# MB9BF52xT register map
File version: 1.2
CPU: 
Registers are 8-bit, read-write, reset 0x0 unless marked. A register's access mark holds for its fields unless they carry their own. Offsets are from the block's base; lines under a group give offsets from that group; [hi:lo] are bit positions; {n}, {i} and the like mark numbered series; 'fields as' and 'values as' point back to an identical list; <NAME> marks a mode.

## Memory map
0x40000000 FLASH_IF blocks up to offset 0xC — Flash Memory
0x40000200 UNIQUE_ID size 0x4
0x40010000 CRG size 0x1 — Clock Unit Registers
0x40011000 HWWDT size 0x4 — Hardware Watchdog Timer
0x40012000 SWWDT size 0x4 — Software Watchdog Timer
0x40015000 DTIM size 0x1C — Dual Timer
0x40020000 MFT0 size 0x2 — Multifunction Timer 0
0x40024000 MFT_PPG size 0x2 — PPG Configuration
0x40025000 BT0 size 0x2 — Base Timer 0
0x40025040 BT1 size 0x2 — Base Timer 0
0x40025080 BT2 size 0x2 — Base Timer 0
0x400250C0 BT3 size 0x2 — Base Timer 0
0x40025100 BTIOSEL03 size 0x2 — Base Timer I/O Select
0x40025200 BT4 size 0x2 — Base Timer 0
0x40025240 BT5 size 0x2 — Base Timer 0
0x40025280 BT6 size 0x2 — Base Timer 0
0x400252C0 BT7 size 0x2 — Base Timer 0
0x40025300 BTIOSEL47 size 0x2 — Base Timer I/O Select
0x40025400 BT8 size 0x2 — Base Timer 0
0x40025440 BT9 size 0x2 — Base Timer 0
0x40025480 BT10 size 0x2 — Base Timer 0
0x400254C0 BT11 size 0x2 — Base Timer 0
0x40025500 BTIOSEL8B size 0x2 — Base Timer I/O Select
0x40025600 BT12 size 0x2 — Base Timer 0
0x40025640 BT13 size 0x2 — Base Timer 0
0x40025680 BT14 size 0x2 — Base Timer 0
0x400256C0 BT15 size 0x2 — Base Timer 0
0x40025700 BTIOSELCF size 0x2 — Base Timer I/O Select
0x40025F00 SBSSR blocks up to offset 0xFE — Software-based Simultaneous Startup Register
0x40026000 QPRC0 size 0x2 — Quadrature Position/Revolution Counter 0
0x40026040 QPRC1 size 0x2 — Quadrature Position/Revolution Counter 0
0x40027000 ADC0 size 0x2 — ADC0 Registers
0x40027100 ADC1 size 0x2 — ADC0 Registers
0x40028000 DAC size 0x3 — D/A Converter
0x4002E000 CRTRIM size 0x1 — CR Trimming Registers
0x40030000 EXTI size 0x4 — External Interrupt and NMI Control
0x40031000 INTREQ size 0x4 — Interrupts
0x40033000 GPIO size 0x740 — General-purpose I/O ports
0x40034000 HDMICEC0 size 0x1 — HDMI-CEC ch.0
0x40034100 HDMICEC1 size 0x1 — HDMI-CEC ch.0
0x40035000 LVD size 0x2 — Low-voltage Detection
0x40035100 DS size 0x1 — Low Power Consumption Mode
0x40036000 USBCLK size 0x1 — USB Clock
0x40037000 CANPRES size 0x1 — CAN Prescaler Register
{0x40038000+0x100*n} MFS{n} size 0x2 (n=0..15) — Multi-function Serial Interface 0
0x40039000 CRC size 0x1 — CRC Registers
0x4003A000 WC size 0x3 — Watch Counter
0x4003B000 RTC size 0x13 — REAL-TIME CLOCK
0x4003F000 EXBUS size 0x80 — External Bus Interface
0x40040000 USB0 blocks up to offset 0x2102 — USB0 Function
0x40060000 DMAC size 0x4 — DMAC Registers
0x40062000 CAN0 size 0xE — CAN0 Registers

## Interrupts
0 CSV (CRG)
1 SWDT (SWWDT)
2 LVD
3 WFG (MFT0)
4 EXTINT0_7 (EXTI)
5 EXTINT8_31 (EXTI)
6 DTIM_QDU (DTIM)
{2n+7} MFS{n}_{n+8}_RX (MFS{n}, MFS{n+8}) (n=0..7)
{2n+8} MFS{n}_{n+8}_TX (MFS{n}, MFS{n+8}) (n=0..7)
23 PPG (MFT_PPG)
24 OSC_PLL_WC_RTC (CRG)
25 ADC0
26 ADC1
28 FRTIM (MFT0)
29 INCAP (MFT0)
30 OUTCOMP (MFT0)
31 BTIM0_7 (BT{n} (n=0..15))
32 CAN0
34 USB0F (USB0)
35 USB0F_USB0H (USB0)
36 HDMICEC0
37 HDMICEC1
{n+38} DMAC{n} (DMAC) (n=0..7)

## FLASH_IF — Flash Memory
Base 0x40000000
0x04 FRWTR 32-bit — Flash Read Wait Register
  [1:0] RWT — Read Wait Cycle
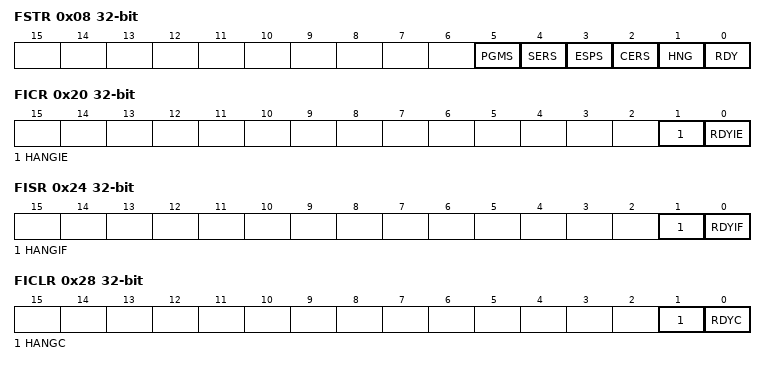
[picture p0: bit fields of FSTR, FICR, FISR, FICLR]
0x08 FSTR 32-bit ro — Flash Status Register
  [5] PGMS — Flash Program Status
  [4] SERS — Flash Sector Erase Status
  [3] ESPS — Flash Erase Suspend Status
  [2] CERS — Flash Chip Erase Status
  [1] HNG — Flash Hang flag
  [0] RDY — Flash Rdy
0x20 FICR 32-bit — Flash Interrupt Control Register
  [1] HANGIE — HANG Interrupt Enable
  [0] RDYIE — RDY Interrupt Enable
0x24 FISR 32-bit — Flash Interrupt Status Register
  [1] HANGIF — HANG Interrupt Flag
  [0] RDYIF — RDY Interrupt Flag
0x28 FICLR 32-bit wo — Flash Interrupt Clear Register
  [1] HANGC rw — HANG Interrupt Clear
  [0] RDYC rw — RDY Interrupt Clear
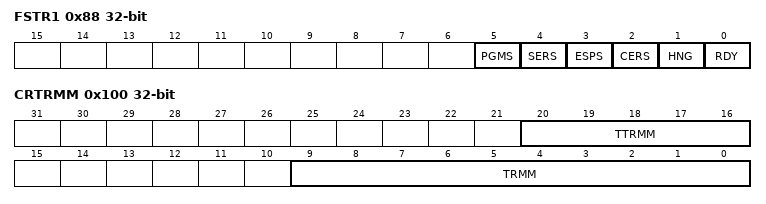
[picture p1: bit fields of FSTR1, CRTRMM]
0x88 FSTR1 32-bit — Flash Status Register 1
  [5] PGMS ro — Flash Program Status
  [4] SERS ro — Flash Sector Erase Status
  [3] ESPS ro — Flash Erase Suspend Status
  [2] CERS ro — Flash Chip Erase Status
  [1] HNG ro — Flash Hang flag
  [0] RDY ro — Flash Rdy
0x100 CRTRMM 32-bit ro reset not defined — CR Trimming Data Mirror Register
  [20:16] TTRMM — CR Temperature Trimming Data Mirror
  [9:0] TRMM — CR Trimming Data Mirror
